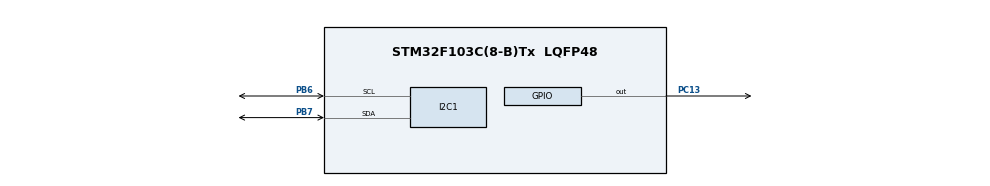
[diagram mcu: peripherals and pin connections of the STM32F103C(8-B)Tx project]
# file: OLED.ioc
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Mcu.Family=STM32F1
Mcu.Name=STM32F103C(8-B)Tx
Mcu.Package=LQFP48
NVIC.PriorityGroup=NVIC_PRIORITYGROUP_4
PA13.Mode=Trace_Asynchronous_SW
PA13.Signal=SYS_JTMS-SWDIO
PA14.Mode=Trace_Asynchronous_SW
PA14.Signal=SYS_JTCK-SWCLK
PB3.Mode=Trace_Asynchronous_SW
PB3.Signal=SYS_JTDO-TRACESWO
PB6.Mode=I2C
PB6.Signal=I2C1_SCL
PB7.Mode=I2C
PB7.Signal=I2C1_SDA
PC13-TAMPER-RTC.Signal=GPIO_Output
ProjectManager.HeapSize=0x200
ProjectManager.StackSize=0x400
ProjectManager.TargetToolchain=MDK-ARM V5
RCC.APB1Freq_Value=8000000
RCC.APB2Freq_Value=8000000
board=custom

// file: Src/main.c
/**
  ******************************************************************************
  * @file           : main.c
  * @brief          : Main program body
  ******************************************************************************
  ** This notice applies to any and all portions of this file
  * that are not between comment pairs USER CODE BEGIN and
  * USER CODE END. Other portions of this file, whether
  * inserted by the user or by software development tools
  * are owned by their respective copyright owners.
  *
  * COPYRIGHT(c) 2018 STMicroelectronics
  *
  * Redistribution and use in source and binary forms, with or without modification,
  * are permitted provided that the following conditions are met:
  *   1. Redistributions of source code must retain the above copyright notice,
  *      this list of conditions and the following disclaimer.
  *   2. Redistributions in binary form must reproduce the above copyright notice,
  *      this list of conditions and the following disclaimer in the documentation
  *      and/or other materials provided with the distribution.
  *   3. Neither the name of STMicroelectronics nor the names of its contributors
  *      may be used to endorse or promote products derived from this software
  *      without specific prior written permission.
  *
  * THIS SOFTWARE IS PROVIDED BY THE COPYRIGHT HOLDERS AND CONTRIBUTORS "AS IS"
  * AND ANY EXPRESS OR IMPLIED WARRANTIES, INCLUDING, BUT NOT LIMITED TO, THE
  * IMPLIED WARRANTIES OF MERCHANTABILITY AND FITNESS FOR A PARTICULAR PURPOSE ARE
  * DISCLAIMED. IN NO EVENT SHALL THE COPYRIGHT HOLDER OR CONTRIBUTORS BE LIABLE
  * FOR ANY DIRECT, INDIRECT, INCIDENTAL, SPECIAL, EXEMPLARY, OR CONSEQUENTIAL
  * DAMAGES (INCLUDING, BUT NOT LIMITED TO, PROCUREMENT OF SUBSTITUTE GOODS OR
  * SERVICES; LOSS OF USE, DATA, OR PROFITS; OR BUSINESS INTERRUPTION) HOWEVER
  * CAUSED AND ON ANY THEORY OF LIABILITY, WHETHER IN CONTRACT, STRICT LIABILITY,
  * OR TORT (INCLUDING NEGLIGENCE OR OTHERWISE) ARISING IN ANY WAY OUT OF THE USE
  * OF THIS SOFTWARE, EVEN IF ADVISED OF THE POSSIBILITY OF SUCH DAMAGE.
  *
  ******************************************************************************
  */
#include "main.h"
#include "stm32f1xx_hal.h"

/* USER CODE BEGIN Includes */
#include "ssd1306.h"
/* USER CODE END Inclues */

I2C_HandleTypeDef hi2c1;

/* USER CODE BEGIN PV */
/* Private variables ---------------------------------------------------------*/

/* USER CODE END PV */

void SystemClock_Config(void);
static void MX_GPIO_Init(void);
static void MX_I2C1_Init(void);

/* USER CODE BEGIN PFP */
/* Private function prototypes -----------------------------------------------*/

/* USER CODE END PFP */

int main(void)
{

  /* MCU Configuration----------------------------------------------------------*/

  /* Reset of all peripherals, Initializes the Flash interface and the Systick. */
  HAL_Init();

  /* Configure the system clock */
  SystemClock_Config();

  /* Initialize all configured peripherals */
  MX_GPIO_Init();
  MX_I2C1_Init();
  /* USER CODE BEGIN 2 */
	ssd1306_Init();
  ssd1306_Fill(Black);
	ssd1306_UpdateScreen();
  /* USER CODE END 2 */

  /* Infinite loop */
  /* USER CODE BEGIN WHILE */
  /* USER CODE END 2 */

  /* Infinite loop */
  /* USER CODE BEGIN WHILE */
	uint32_t lst = 0, cu, i;
	char buf[10];
  while (1)
  {
  /* USER CODE END WHILE */
		cu = HAL_GetTick();
		ssd1306_SetCursor(0,0);
		sprintf(buf, "fps: %.3f", 1000.0 / (double)(cu - lst));
		ssd1306_WriteString(buf, Font_7x10, White);
		ssd1306_SetCursor(SSD1306_WIDTH/2-(7*2.5),SSD1306_HEIGHT/2-(5));
		ssd1306_WriteString("STM32", Font_7x10, White);
		i++;
		ssd1306_SetCursor(30,40);
		sprintf(buf, "%d", i);
		ssd1306_WriteString(buf,Font_7x10,White);
		ssd1306_UpdateScreen();
		lst = cu;
  }

}

void SystemClock_Config(void)
{

  RCC_OscInitTypeDef RCC_OscInitStruct;
  RCC_ClkInitTypeDef RCC_ClkInitStruct;

    /**Initializes the CPU, AHB and APB busses clocks
    */
  RCC_OscInitStruct.OscillatorType = RCC_OSCILLATORTYPE_HSI;
  RCC_OscInitStruct.HSIState = RCC_HSI_ON;
  RCC_OscInitStruct.HSICalibrationValue = 16;
  RCC_OscInitStruct.PLL.PLLState = RCC_PLL_NONE;
  if (HAL_RCC_OscConfig(&RCC_OscInitStruct) != HAL_OK)
  {
    _Error_Handler(__FILE__, __LINE__);
  }

    /**Initializes the CPU, AHB and APB busses clocks
    */
  RCC_ClkInitStruct.ClockType = RCC_CLOCKTYPE_HCLK|RCC_CLOCKTYPE_SYSCLK
                              |RCC_CLOCKTYPE_PCLK1|RCC_CLOCKTYPE_PCLK2;
  RCC_ClkInitStruct.SYSCLKSource = RCC_SYSCLKSOURCE_HSI;
  RCC_ClkInitStruct.AHBCLKDivider = RCC_SYSCLK_DIV1;
  RCC_ClkInitStruct.APB1CLKDivider = RCC_HCLK_DIV1;
  RCC_ClkInitStruct.APB2CLKDivider = RCC_HCLK_DIV1;

  if (HAL_RCC_ClockConfig(&RCC_ClkInitStruct, FLASH_LATENCY_0) != HAL_OK)
  {
    _Error_Handler(__FILE__, __LINE__);
  }

    /**Configure the Systick interrupt time
    */
  HAL_SYSTICK_Config(HAL_RCC_GetHCLKFreq()/1000);

    /**Configure the Systick
    */
  HAL_SYSTICK_CLKSourceConfig(SYSTICK_CLKSOURCE_HCLK);

  /* SysTick_IRQn interrupt configuration */
  HAL_NVIC_SetPriority(SysTick_IRQn, 0, 0);
}

/* I2C1 init function */
static void MX_I2C1_Init(void)
{

  hi2c1.Instance = I2C1;
  hi2c1.Init.ClockSpeed = 100000;
  hi2c1.Init.DutyCycle = I2C_DUTYCYCLE_2;
  hi2c1.Init.OwnAddress1 = 0;
  hi2c1.Init.AddressingMode = I2C_ADDRESSINGMODE_7BIT;
  hi2c1.Init.DualAddressMode = I2C_DUALADDRESS_DISABLE;
  hi2c1.Init.OwnAddress2 = 0;
  hi2c1.Init.GeneralCallMode = I2C_GENERALCALL_DISABLE;
  hi2c1.Init.NoStretchMode = I2C_NOSTRETCH_DISABLE;
  if (HAL_I2C_Init(&hi2c1) != HAL_OK)
  {
    _Error_Handler(__FILE__, __LINE__);
  }

}

/** Configure pins as
        * Analog
        * Input
        * Output
        * EVENT_OUT
        * EXTI
*/
static void MX_GPIO_Init(void)
{

  GPIO_InitTypeDef GPIO_InitStruct;

  /* GPIO Ports Clock Enable */
  __HAL_RCC_GPIOC_CLK_ENABLE();
  __HAL_RCC_GPIOA_CLK_ENABLE();
  __HAL_RCC_GPIOB_CLK_ENABLE();

  /*Configure GPIO pin Output Level */
  HAL_GPIO_WritePin(GPIOC, GPIO_PIN_13, GPIO_PIN_RESET);

  /*Configure GPIO pin : PC13 */
  GPIO_InitStruct.Pin = GPIO_PIN_13;
  GPIO_InitStruct.Mode = GPIO_MODE_OUTPUT_PP;
  GPIO_InitStruct.Pull = GPIO_NOPULL;
  GPIO_InitStruct.Speed = GPIO_SPEED_FREQ_LOW;
  HAL_GPIO_Init(GPIOC, &GPIO_InitStruct);

}

void _Error_Handler(char *file, int line)
{
  while(1)
  {
  }
}

/************************ (C) COPYRIGHT STMicroelectronics *****END OF FILE****/
